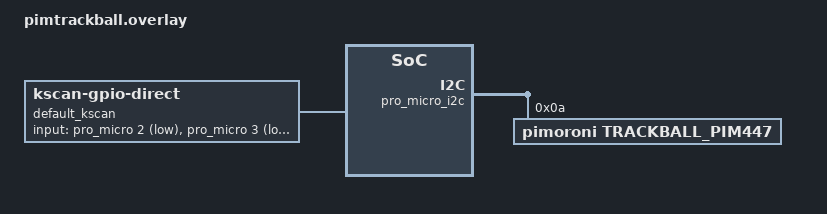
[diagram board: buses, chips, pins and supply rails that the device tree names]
// pimtrackball.overlay

#include "splitmouse.dtsi" // Notice that the main dtsi files are included in the overlay.
#include <dt-bindings/zmk/trackball_pim447.h> // for PIM447_MOVE and PIM447_SCROLL constants

/ {
    chosen {
        zmk,kscan = &default_kscan;
    };

    default_kscan: kscan {
        compatible = "zmk,kscan-gpio-direct";
        label = "default_kscan";

        input-gpios
            = <&pro_micro 2 (GPIO_ACTIVE_LOW | GPIO_PULL_UP)> // Row A from the schematic file
            , <&pro_micro 3 (GPIO_ACTIVE_LOW | GPIO_PULL_UP)> // Row B from the schematic file
            //, <&pro_micro 3 (GPIO_ACTIVE_LOW | GPIO_PULL_UP)> // Row C from the schematic file
            ;
    };
};

&pro_micro_i2c {
	status = "okay";
	trackball_pim447@a {
		compatible = "pimoroni,trackball_pim447";
		reg = <0xa>;
		label = "TRACKBALL_PIM447";
		
		move-factor = <2>;      // Increase pointer velocity (default: 1)
		//invert-move-x;          // Invert pointer X axis (left is right, and vice versa)
		//invert-move-y;          // Invert pointer Y axis (up is down, and vice versa)
		button = <1>;           // Send right-click when pressing the ball (default: 0 = left click, 1 = right click, 2 = middle click?)
		//swap-axes;              // Swap X and Y axes (horizontal is vertical, and vice versa)
		scroll-divisor = <1>;   // Increase wheel velocity (default: 2)
		//invert-scroll-x;        // Invert wheel X axis (left is right, and vice versa)
		//invert-scroll-y;        // Invert wheel Y axis (up is down, and vice versa)
		mode = <1>                //PIM447_SCROLL>;  Act as mouse wheels at startup (default: PIM447_MOVE for a pointer)
	};
};
